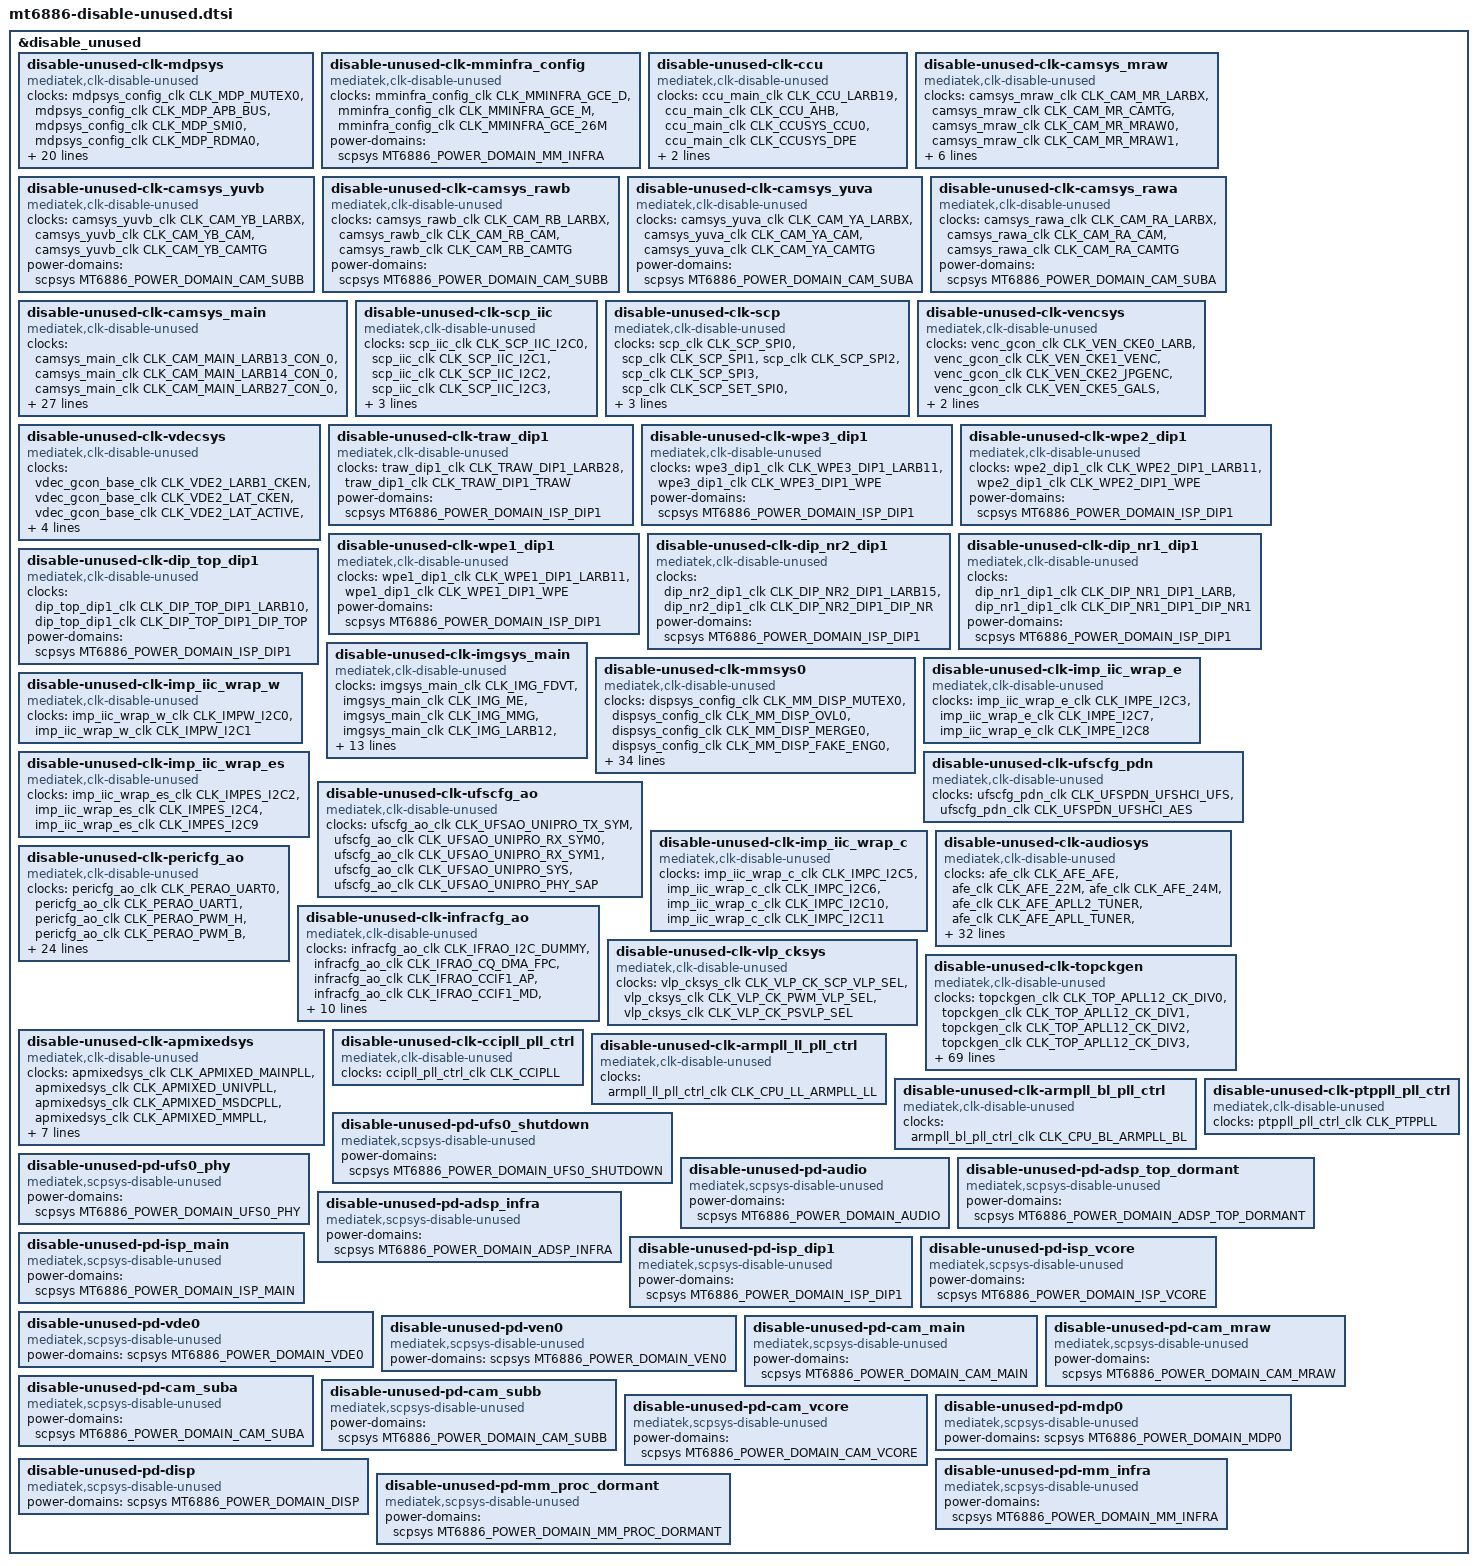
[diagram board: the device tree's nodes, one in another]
// SPDX-License-Identifier: GPL-2.0-only OR BSD-2-Clause
/*
 * Copyright (C) 2022 MediaTek Inc.
 * Author: Chong-ming Wei <chong-ming.wei@mediatek.com>
 */

&disable_unused {
	status = "okay";
	disable-unused-clk-mdpsys {
		compatible = "mediatek,clk-disable-unused";
		clocks =
			<&mdpsys_config_clk CLK_MDP_MUTEX0>,
			<&mdpsys_config_clk CLK_MDP_APB_BUS>,
			<&mdpsys_config_clk CLK_MDP_SMI0>,
			<&mdpsys_config_clk CLK_MDP_RDMA0>,
			<&mdpsys_config_clk CLK_MDP_HDR0>,
			<&mdpsys_config_clk CLK_MDP_AAL0>,
			<&mdpsys_config_clk CLK_MDP_RSZ0>,
			<&mdpsys_config_clk CLK_MDP_TDSHP0>,
			<&mdpsys_config_clk CLK_MDP_COLOR0>,
			<&mdpsys_config_clk CLK_MDP_WROT0>,
			<&mdpsys_config_clk CLK_MDP_FAKE_ENG0>,
			<&mdpsys_config_clk CLK_MDP_DL_RELAY0>,
			<&mdpsys_config_clk CLK_MDP_DL_RELAY1>,
			<&mdpsys_config_clk CLK_MDP_RDMA1>,
			<&mdpsys_config_clk CLK_MDP_HDR1>,
			<&mdpsys_config_clk CLK_MDP_AAL1>,
			<&mdpsys_config_clk CLK_MDP_RSZ1>,
			<&mdpsys_config_clk CLK_MDP_TDSHP1>,
			<&mdpsys_config_clk CLK_MDP_COLOR1>,
			<&mdpsys_config_clk CLK_MDP_WROT1>,
			<&mdpsys_config_clk CLK_MDP_DLO_ASYNC0>,
			<&mdpsys_config_clk CLK_MDP_DLO_ASYNC1>,
			<&mdpsys_config_clk CLK_MDP_HRE_TOP_MDPSYS>;
			power-domains = <&scpsys MT6886_POWER_DOMAIN_MDP0>;
	};

	disable-unused-clk-mminfra_config {
		compatible = "mediatek,clk-disable-unused";
		clocks =
			<&mminfra_config_clk CLK_MMINFRA_GCE_D>,
			<&mminfra_config_clk CLK_MMINFRA_GCE_M>,
			<&mminfra_config_clk CLK_MMINFRA_GCE_26M>;
			power-domains = <&scpsys MT6886_POWER_DOMAIN_MM_INFRA>;
	};

	disable-unused-clk-ccu {
		compatible = "mediatek,clk-disable-unused";
		clocks =
			<&ccu_main_clk CLK_CCU_LARB19>,
			<&ccu_main_clk CLK_CCU_AHB>,
			<&ccu_main_clk CLK_CCUSYS_CCU0>,
			<&ccu_main_clk CLK_CCUSYS_DPE>;
			power-domains = <&scpsys MT6886_POWER_DOMAIN_CAM_MAIN>;
	};

	disable-unused-clk-camsys_mraw {
		compatible = "mediatek,clk-disable-unused";
		clocks =
			<&camsys_mraw_clk CLK_CAM_MR_LARBX>,
			<&camsys_mraw_clk CLK_CAM_MR_CAMTG>,
			<&camsys_mraw_clk CLK_CAM_MR_MRAW0>,
			<&camsys_mraw_clk CLK_CAM_MR_MRAW1>,
			<&camsys_mraw_clk CLK_CAM_MR_MRAW2>,
			<&camsys_mraw_clk CLK_CAM_MR_MRAW3>,
			<&camsys_mraw_clk CLK_CAM_MR_PDA0>,
			<&camsys_mraw_clk CLK_CAM_MR_PDA1>;
			power-domains = <&scpsys MT6886_POWER_DOMAIN_CAM_MRAW>;
	};

	disable-unused-clk-camsys_yuvb {
		compatible = "mediatek,clk-disable-unused";
		clocks =
			<&camsys_yuvb_clk CLK_CAM_YB_LARBX>,
			<&camsys_yuvb_clk CLK_CAM_YB_CAM>,
			<&camsys_yuvb_clk CLK_CAM_YB_CAMTG>;
			power-domains = <&scpsys MT6886_POWER_DOMAIN_CAM_SUBB>;
	};

	disable-unused-clk-camsys_rawb {
		compatible = "mediatek,clk-disable-unused";
		clocks =
			<&camsys_rawb_clk CLK_CAM_RB_LARBX>,
			<&camsys_rawb_clk CLK_CAM_RB_CAM>,
			<&camsys_rawb_clk CLK_CAM_RB_CAMTG>;
			power-domains = <&scpsys MT6886_POWER_DOMAIN_CAM_SUBB>;
	};

	disable-unused-clk-camsys_yuva {
		compatible = "mediatek,clk-disable-unused";
		clocks =
			<&camsys_yuva_clk CLK_CAM_YA_LARBX>,
			<&camsys_yuva_clk CLK_CAM_YA_CAM>,
			<&camsys_yuva_clk CLK_CAM_YA_CAMTG>;
			power-domains = <&scpsys MT6886_POWER_DOMAIN_CAM_SUBA>;
	};

	disable-unused-clk-camsys_rawa {
		compatible = "mediatek,clk-disable-unused";
		clocks =
			<&camsys_rawa_clk CLK_CAM_RA_LARBX>,
			<&camsys_rawa_clk CLK_CAM_RA_CAM>,
			<&camsys_rawa_clk CLK_CAM_RA_CAMTG>;
			power-domains = <&scpsys MT6886_POWER_DOMAIN_CAM_SUBA>;
	};

	disable-unused-clk-camsys_main {
		compatible = "mediatek,clk-disable-unused";
		clocks =
			<&camsys_main_clk CLK_CAM_MAIN_LARB13_CON_0>,
			<&camsys_main_clk CLK_CAM_MAIN_LARB14_CON_0>,
			<&camsys_main_clk CLK_CAM_MAIN_LARB27_CON_0>,
			<&camsys_main_clk CLK_CAM_MAIN_LARB29_CON_0>,
			<&camsys_main_clk CLK_CAM_MAIN_CAM_CON_0>,
			<&camsys_main_clk CLK_CAM_MAIN_CAM_SUBA_CON_0>,
			<&camsys_main_clk CLK_CAM_MAIN_CAM_SUBB_CON_0>,
			<&camsys_main_clk CLK_CAM_MAIN_CAM_SUBC_CON_0>,
			<&camsys_main_clk CLK_CAM_MAIN_CAM_MRAW_CON_0>,
			<&camsys_main_clk CLK_CAM_MAIN_CAMTG_CON_0>,
			<&camsys_main_clk CLK_CAM_MAIN_SENINF_CON_0>,
			<&camsys_main_clk CLK_CAM_MAIN_CAMSV_TOP_CON_0>,
			<&camsys_main_clk CLK_CAM_MAIN_ADLRD_CON_0>,
			<&camsys_main_clk CLK_CAM_MAIN_ADLWR_CON_0>,
			<&camsys_main_clk CLK_CAM_MAIN_UISP_CON_0>,
			<&camsys_main_clk CLK_CAM_MAIN_FAKE_ENG_CON_0>,
			<&camsys_main_clk CLK_CAM_MAIN_CAM2MM0_GALS_CON_0>,
			<&camsys_main_clk CLK_CAM_MAIN_CAM2MM1_GALS_CON_0>,
			<&camsys_main_clk CLK_CAM_MAIN_CAM2SYS_GALS_CON_0>,
			<&camsys_main_clk CLK_CAM_MAIN_CAM2MM2_GALS_CON_0>,
			<&camsys_main_clk CLK_CAM_MAIN_CCUSYS_CON_0>,
			<&camsys_main_clk CLK_CAM_MAIN_IPS_CON_0>,
			<&camsys_main_clk CLK_CAM_MAIN_CAMSV_A_CON_1>,
			<&camsys_main_clk CLK_CAM_MAIN_CAMSV_B_CON_1>,
			<&camsys_main_clk CLK_CAM_MAIN_CAMSV_C_CON_1>,
			<&camsys_main_clk CLK_CAM_MAIN_CAMSV_D_CON_1>,
			<&camsys_main_clk CLK_CAM_MAIN_CAMSV_E_CON_1>,
			<&camsys_main_clk CLK_CAM_MAIN_CAMSV_CON_1>;
			power-domains = <&scpsys MT6886_POWER_DOMAIN_CAM_MAIN>;
	};

	disable-unused-clk-scp_iic {
		compatible = "mediatek,clk-disable-unused";
		clocks =
			<&scp_iic_clk CLK_SCP_IIC_I2C0>,
			<&scp_iic_clk CLK_SCP_IIC_I2C1>,
			<&scp_iic_clk CLK_SCP_IIC_I2C2>,
			<&scp_iic_clk CLK_SCP_IIC_I2C3>,
			<&scp_iic_clk CLK_SCP_IIC_I2C4>,
			<&scp_iic_clk CLK_SCP_IIC_I2C5>,
			<&scp_iic_clk CLK_SCP_IIC_I2C6>;
	};

	disable-unused-clk-scp {
		compatible = "mediatek,clk-disable-unused";
		clocks =
			<&scp_clk CLK_SCP_SPI0>,
			<&scp_clk CLK_SCP_SPI1>,
			<&scp_clk CLK_SCP_SPI2>,
			<&scp_clk CLK_SCP_SPI3>,
			<&scp_clk CLK_SCP_SET_SPI0>,
			<&scp_clk CLK_SCP_SET_SPI1>,
			<&scp_clk CLK_SCP_SET_SPI2>,
			<&scp_clk CLK_SCP_SET_SPI3>;
	};

	disable-unused-clk-vencsys {
		compatible = "mediatek,clk-disable-unused";
		clocks =
			<&venc_gcon_clk CLK_VEN_CKE0_LARB>,
			<&venc_gcon_clk CLK_VEN_CKE1_VENC>,
			<&venc_gcon_clk CLK_VEN_CKE2_JPGENC>,
			<&venc_gcon_clk CLK_VEN_CKE5_GALS>,
			<&venc_gcon_clk CLK_VEN_CKE6_GALS_SRAM>;
			power-domains = <&scpsys MT6886_POWER_DOMAIN_VEN0>;
	};

	disable-unused-clk-vdecsys {
		compatible = "mediatek,clk-disable-unused";
		clocks =
			<&vdec_gcon_base_clk CLK_VDE2_LARB1_CKEN>,
			<&vdec_gcon_base_clk CLK_VDE2_LAT_CKEN>,
			<&vdec_gcon_base_clk CLK_VDE2_LAT_ACTIVE>,
			<&vdec_gcon_base_clk CLK_VDE2_MINI_MDP_EN>,
			<&vdec_gcon_base_clk CLK_VDE2_VDEC_CKEN>,
			<&vdec_gcon_base_clk CLK_VDE2_VDEC_ACTIVE>;
			power-domains = <&scpsys MT6886_POWER_DOMAIN_VDE0>;
	};

	disable-unused-clk-traw_dip1 {
		compatible = "mediatek,clk-disable-unused";
		clocks =
			<&traw_dip1_clk CLK_TRAW_DIP1_LARB28>,
			<&traw_dip1_clk CLK_TRAW_DIP1_TRAW>;
			power-domains = <&scpsys MT6886_POWER_DOMAIN_ISP_DIP1>;
	};

	disable-unused-clk-wpe3_dip1 {
		compatible = "mediatek,clk-disable-unused";
		clocks =
			<&wpe3_dip1_clk CLK_WPE3_DIP1_LARB11>,
			<&wpe3_dip1_clk CLK_WPE3_DIP1_WPE>;
			power-domains = <&scpsys MT6886_POWER_DOMAIN_ISP_DIP1>;
	};

	disable-unused-clk-wpe2_dip1 {
		compatible = "mediatek,clk-disable-unused";
		clocks =
			<&wpe2_dip1_clk CLK_WPE2_DIP1_LARB11>,
			<&wpe2_dip1_clk CLK_WPE2_DIP1_WPE>;
			power-domains = <&scpsys MT6886_POWER_DOMAIN_ISP_DIP1>;
	};

	disable-unused-clk-wpe1_dip1 {
		compatible = "mediatek,clk-disable-unused";
		clocks =
			<&wpe1_dip1_clk CLK_WPE1_DIP1_LARB11>,
			<&wpe1_dip1_clk CLK_WPE1_DIP1_WPE>;
			power-domains = <&scpsys MT6886_POWER_DOMAIN_ISP_DIP1>;
	};

	disable-unused-clk-dip_nr2_dip1 {
		compatible = "mediatek,clk-disable-unused";
		clocks =
			<&dip_nr2_dip1_clk CLK_DIP_NR2_DIP1_LARB15>,
			<&dip_nr2_dip1_clk CLK_DIP_NR2_DIP1_DIP_NR>;
			power-domains = <&scpsys MT6886_POWER_DOMAIN_ISP_DIP1>;
	};

	disable-unused-clk-dip_nr1_dip1 {
		compatible = "mediatek,clk-disable-unused";
		clocks =
			<&dip_nr1_dip1_clk CLK_DIP_NR1_DIP1_LARB>,
			<&dip_nr1_dip1_clk CLK_DIP_NR1_DIP1_DIP_NR1>;
			power-domains = <&scpsys MT6886_POWER_DOMAIN_ISP_DIP1>;
	};

	disable-unused-clk-dip_top_dip1 {
		compatible = "mediatek,clk-disable-unused";
		clocks =
			<&dip_top_dip1_clk CLK_DIP_TOP_DIP1_LARB10>,
			<&dip_top_dip1_clk CLK_DIP_TOP_DIP1_DIP_TOP>;
			power-domains = <&scpsys MT6886_POWER_DOMAIN_ISP_DIP1>;
	};

	disable-unused-clk-imgsys_main {
		compatible = "mediatek,clk-disable-unused";
		clocks =
			<&imgsys_main_clk CLK_IMG_FDVT>,
			<&imgsys_main_clk CLK_IMG_ME>,
			<&imgsys_main_clk CLK_IMG_MMG>,
			<&imgsys_main_clk CLK_IMG_LARB12>,
			<&imgsys_main_clk CLK_IMG_LARB9>,
			<&imgsys_main_clk CLK_IMG_TRAW0>,
			<&imgsys_main_clk CLK_IMG_TRAW1>,
			<&imgsys_main_clk CLK_IMG_VCORE_GALS>,
			<&imgsys_main_clk CLK_IMG_DIP0>,
			<&imgsys_main_clk CLK_IMG_WPE0>,
			<&imgsys_main_clk CLK_IMG_IPE>,
			<&imgsys_main_clk CLK_IMG_WPE1>,
			<&imgsys_main_clk CLK_IMG_WPE2>,
			<&imgsys_main_clk CLK_IMG_AVS>,
			<&imgsys_main_clk CLK_IMG_GALS>;
			power-domains = <&scpsys MT6886_POWER_DOMAIN_ISP_MAIN>;
	};

	disable-unused-clk-mmsys0 {
		compatible = "mediatek,clk-disable-unused";
		clocks =
			<&dispsys_config_clk CLK_MM_DISP_MUTEX0>,
			<&dispsys_config_clk CLK_MM_DISP_OVL0>,
			<&dispsys_config_clk CLK_MM_DISP_MERGE0>,
			<&dispsys_config_clk CLK_MM_DISP_FAKE_ENG0>,
			<&dispsys_config_clk CLK_MM_INLINEROT0>,
			<&dispsys_config_clk CLK_MM_DISP_WDMA0>,
			<&dispsys_config_clk CLK_MM_DISP_FAKE_ENG1>,
			<&dispsys_config_clk CLK_MM_DISP_OVL0_2L_NW>,
			<&dispsys_config_clk CLK_MM_DISP_RDMA0>,
			<&dispsys_config_clk CLK_MM_DISP_RDMA1>,
			<&dispsys_config_clk CLK_MM_DISP_RSZ0>,
			<&dispsys_config_clk CLK_MM_DISP_COLOR0>,
			<&dispsys_config_clk CLK_MM_DISP_CCORR0>,
			<&dispsys_config_clk CLK_MM_DISP_CCORR1>,
			<&dispsys_config_clk CLK_MM_DISP_AAL0>,
			<&dispsys_config_clk CLK_MM_DISP_GAMMA0>,
			<&dispsys_config_clk CLK_MM_DISP_POSTMASK0>,
			<&dispsys_config_clk CLK_MM_DISP_DITHER0>,
			<&dispsys_config_clk CLK_MM_DISP_CM0>,
			<&dispsys_config_clk CLK_MM_DISP_SPR0>,
			<&dispsys_config_clk CLK_MM_DISP_DSC_WRAP0>,
			<&dispsys_config_clk CLK_MM_FMM_DISP_DSI0>,
			<&dispsys_config_clk CLK_MM_DISP_UFBC_WDMA0>,
			<&dispsys_config_clk CLK_MM_DISP_WDMA1>,
			<&dispsys_config_clk CLK_MM_APB_BUS>,
			<&dispsys_config_clk CLK_MM_DISP_C3D0>,
			<&dispsys_config_clk CLK_MM_DISP_Y2R0>,
			<&dispsys_config_clk CLK_MM_DISP_CHIST0>,
			<&dispsys_config_clk CLK_MM_DISP_CHIST1>,
			<&dispsys_config_clk CLK_MM_DISP_OVL0_2L>,
			<&dispsys_config_clk CLK_MM_DISP_DLI_ASYNC3>,
			<&dispsys_config_clk CLK_MM_DISP_DLO_ASYNC3>,
			<&dispsys_config_clk CLK_MM_DISP_OVL1_2L>,
			<&dispsys_config_clk CLK_MM_DISP_OVL1_2L_NW>,
			<&dispsys_config_clk CLK_MM_SMI_COMMON>,
			<&dispsys_config_clk CLK_MM_DISP_DSI0>,
			<&dispsys_config_clk CLK_MM_SIG_EMI>;
			power-domains = <&scpsys MT6886_POWER_DOMAIN_DISP>;
	};

	disable-unused-clk-imp_iic_wrap_e {
		compatible = "mediatek,clk-disable-unused";
		clocks =
			<&imp_iic_wrap_e_clk CLK_IMPE_I2C3>,
			<&imp_iic_wrap_e_clk CLK_IMPE_I2C7>,
			<&imp_iic_wrap_e_clk CLK_IMPE_I2C8>;
	};

	disable-unused-clk-imp_iic_wrap_w {
		compatible = "mediatek,clk-disable-unused";
		clocks =
			<&imp_iic_wrap_w_clk CLK_IMPW_I2C0>,
			<&imp_iic_wrap_w_clk CLK_IMPW_I2C1>;
	};

	disable-unused-clk-imp_iic_wrap_es {
		compatible = "mediatek,clk-disable-unused";
		clocks =
			<&imp_iic_wrap_es_clk CLK_IMPES_I2C2>,
			<&imp_iic_wrap_es_clk CLK_IMPES_I2C4>,
			<&imp_iic_wrap_es_clk CLK_IMPES_I2C9>;
	};

	disable-unused-clk-ufscfg_pdn {
		compatible = "mediatek,clk-disable-unused";
		clocks =
			<&ufscfg_pdn_clk CLK_UFSPDN_UFSHCI_UFS>,
			<&ufscfg_pdn_clk CLK_UFSPDN_UFSHCI_AES>;
	};

	disable-unused-clk-ufscfg_ao {
		compatible = "mediatek,clk-disable-unused";
		clocks =
			<&ufscfg_ao_clk CLK_UFSAO_UNIPRO_TX_SYM>,
			<&ufscfg_ao_clk CLK_UFSAO_UNIPRO_RX_SYM0>,
			<&ufscfg_ao_clk CLK_UFSAO_UNIPRO_RX_SYM1>,
			<&ufscfg_ao_clk CLK_UFSAO_UNIPRO_SYS>,
			<&ufscfg_ao_clk CLK_UFSAO_UNIPRO_PHY_SAP>;
	};

	disable-unused-clk-imp_iic_wrap_c {
		compatible = "mediatek,clk-disable-unused";
		clocks =
			<&imp_iic_wrap_c_clk CLK_IMPC_I2C5>,
			<&imp_iic_wrap_c_clk CLK_IMPC_I2C6>,
			<&imp_iic_wrap_c_clk CLK_IMPC_I2C10>,
			<&imp_iic_wrap_c_clk CLK_IMPC_I2C11>;
	};

	disable-unused-clk-audiosys {
		compatible = "mediatek,clk-disable-unused";
		clocks =
			<&afe_clk CLK_AFE_AFE>,
			<&afe_clk CLK_AFE_22M>,
			<&afe_clk CLK_AFE_24M>,
			<&afe_clk CLK_AFE_APLL2_TUNER>,
			<&afe_clk CLK_AFE_APLL_TUNER>,
			<&afe_clk CLK_AFE_TDM>,
			<&afe_clk CLK_AFE_ADC>,
			<&afe_clk CLK_AFE_DAC>,
			<&afe_clk CLK_AFE_DAC_PREDIS>,
			<&afe_clk CLK_AFE_TML>,
			<&afe_clk CLK_AFE_NLE>,
			<&afe_clk CLK_AFE_GENERAL3_ASRC>,
			<&afe_clk CLK_AFE_CONNSYS_I2S_ASRC>,
			<&afe_clk CLK_AFE_GENERAL1_ASRC>,
			<&afe_clk CLK_AFE_GENERAL2_ASRC>,
			<&afe_clk CLK_AFE_DAC_HIRES>,
			<&afe_clk CLK_AFE_ADC_HIRES>,
			<&afe_clk CLK_AFE_ADC_HIRES_TML>,
			<&afe_clk CLK_AFE_ADDA6_ADC>,
			<&afe_clk CLK_AFE_ADDA6_ADC_HIRES>,
			<&afe_clk CLK_AFE_3RD_DAC>,
			<&afe_clk CLK_AFE_3RD_DAC_PREDIS>,
			<&afe_clk CLK_AFE_3RD_DAC_TML>,
			<&afe_clk CLK_AFE_3RD_DAC_HIRES>,
			<&afe_clk CLK_AFE_I2S5_BCLK>,
			<&afe_clk CLK_AFE_I2S6_BCLK>,
			<&afe_clk CLK_AFE_I2S7_BCLK>,
			<&afe_clk CLK_AFE_I2S8_BCLK>,
			<&afe_clk CLK_AFE_I2S9_BCLK>,
			<&afe_clk CLK_AFE_ETDM_IN0_BCLK>,
			<&afe_clk CLK_AFE_ETDM_OUT0_BCLK>,
			<&afe_clk CLK_AFE_I2S1_BCLK>,
			<&afe_clk CLK_AFE_I2S2_BCLK>,
			<&afe_clk CLK_AFE_I2S3_BCLK>,
			<&afe_clk CLK_AFE_I2S4_BCLK>,
			<&afe_clk CLK_AFE_ETDM_IN1_BCLK>,
			<&afe_clk CLK_AFE_ETDM_OUT1_BCLK>;
			power-domains = <&scpsys MT6886_POWER_DOMAIN_AUDIO>;
	};

	disable-unused-clk-pericfg_ao {
		compatible = "mediatek,clk-disable-unused";
		clocks =
			<&pericfg_ao_clk CLK_PERAO_UART0>,
			<&pericfg_ao_clk CLK_PERAO_UART1>,
			<&pericfg_ao_clk CLK_PERAO_PWM_H>,
			<&pericfg_ao_clk CLK_PERAO_PWM_B>,
			<&pericfg_ao_clk CLK_PERAO_PWM_FB1>,
			<&pericfg_ao_clk CLK_PERAO_PWM_FB2>,
			<&pericfg_ao_clk CLK_PERAO_PWM_FB3>,
			<&pericfg_ao_clk CLK_PERAO_PWM_FB4>,
			<&pericfg_ao_clk CLK_PERAO_BTIF_B>,
			<&pericfg_ao_clk CLK_PERAO_DISP_PWM0>,
			<&pericfg_ao_clk CLK_PERAO_SPI0_B>,
			<&pericfg_ao_clk CLK_PERAO_SPI1_B>,
			<&pericfg_ao_clk CLK_PERAO_SPI2_B>,
			<&pericfg_ao_clk CLK_PERAO_SPI3_B>,
			<&pericfg_ao_clk CLK_PERAO_SPI4_B>,
			<&pericfg_ao_clk CLK_PERAO_SPI5_B>,
			<&pericfg_ao_clk CLK_PERAO_SPI6_B>,
			<&pericfg_ao_clk CLK_PERAO_SPI7_B>,
			<&pericfg_ao_clk CLK_PERAO_APDMA>,
			<&pericfg_ao_clk CLK_PERAO_USB_SYS>,
			<&pericfg_ao_clk CLK_PERAO_USB_XHCI>,
			<&pericfg_ao_clk CLK_PERAO_USB_BUS>,
			<&pericfg_ao_clk CLK_PERAO_MSDC1>,
			<&pericfg_ao_clk CLK_PERAO_MSDC1_H>,
			<&pericfg_ao_clk CLK_PERAO_AUDIO_SLV_CKP>,
			<&pericfg_ao_clk CLK_PERAO_AUDIO_MST_CKP>,
			<&pericfg_ao_clk CLK_PERAO_INTBUS_CKP>,
			<&pericfg_ao_clk CLK_PERAO_AUDIO_MST_IDLE_EN>;
	};

	disable-unused-clk-infracfg_ao {
		compatible = "mediatek,clk-disable-unused";
		clocks =
			<&infracfg_ao_clk CLK_IFRAO_I2C_DUMMY>,
			<&infracfg_ao_clk CLK_IFRAO_CQ_DMA_FPC>,
			<&infracfg_ao_clk CLK_IFRAO_CCIF1_AP>,
			<&infracfg_ao_clk CLK_IFRAO_CCIF1_MD>,
			<&infracfg_ao_clk CLK_IFRAO_CCIF_AP>,
			<&infracfg_ao_clk CLK_IFRAO_CCIF_MD>,
			<&infracfg_ao_clk CLK_IFRAO_CLDMA_BCLK>,
			<&infracfg_ao_clk CLK_IFRAO_CQ_DMA>,
			<&infracfg_ao_clk CLK_IFRAO_CCIF5_MD>,
			<&infracfg_ao_clk CLK_IFRAO_CCIF2_AP>,
			<&infracfg_ao_clk CLK_IFRAO_CCIF2_MD>,
			<&infracfg_ao_clk CLK_IFRAO_DPMAIF_MAIN>,
			<&infracfg_ao_clk CLK_IFRAO_CCIF4_MD>,
			<&infracfg_ao_clk CLK_IFRAO_RG_MMW_DPMAIF26M>;
	};

	disable-unused-clk-vlp_cksys {
		compatible = "mediatek,clk-disable-unused";
		clocks =
			<&vlp_cksys_clk CLK_VLP_CK_SCP_VLP_SEL>,
			<&vlp_cksys_clk CLK_VLP_CK_PWM_VLP_SEL>,
			<&vlp_cksys_clk CLK_VLP_CK_PSVLP_SEL>;
	};

	disable-unused-clk-topckgen {
		compatible = "mediatek,clk-disable-unused";
		clocks =
			<&topckgen_clk CLK_TOP_APLL12_CK_DIV0>,
			<&topckgen_clk CLK_TOP_APLL12_CK_DIV1>,
			<&topckgen_clk CLK_TOP_APLL12_CK_DIV2>,
			<&topckgen_clk CLK_TOP_APLL12_CK_DIV3>,
			<&topckgen_clk CLK_TOP_APLL12_CK_DIV4>,
			<&topckgen_clk CLK_TOP_APLL12_CK_DIVB>,
			<&topckgen_clk CLK_TOP_APLL12_CK_DIV5>,
			<&topckgen_clk CLK_TOP_APLL12_CK_DIV6>,
			<&topckgen_clk CLK_TOP_APLL12_CK_DIV7>,
			<&topckgen_clk CLK_TOP_APLL12_CK_DIV8>,
			<&topckgen_clk CLK_TOP_APLL12_CK_DIV9>,
			<&topckgen_clk CLK_TOP_APLL12_CK_DIV_ETDM_IN1>,
			<&topckgen_clk CLK_TOP_APLL12_CK_DIV_ETDM_OUT1>,
			<&topckgen_clk CLK_TOP_DISP0_SEL>,
			<&topckgen_clk CLK_TOP_MDP0_SEL>,
			<&topckgen_clk CLK_TOP_MMINFRA_SEL>,
			<&topckgen_clk CLK_TOP_MMUP_SEL>,
			<&topckgen_clk CLK_TOP_DSP_SEL>,
			<&topckgen_clk CLK_TOP_CAMTG_SEL>,
			<&topckgen_clk CLK_TOP_CAMTG2_SEL>,
			<&topckgen_clk CLK_TOP_CAMTG3_SEL>,
			<&topckgen_clk CLK_TOP_CAMTG4_SEL>,
			<&topckgen_clk CLK_TOP_CAMTG5_SEL>,
			<&topckgen_clk CLK_TOP_CAMTG6_SEL>,
			<&topckgen_clk CLK_TOP_UART_SEL>,
			<&topckgen_clk CLK_TOP_SPI_SEL>,
			<&topckgen_clk CLK_TOP_MSDC_MACRO_SEL>,
			<&topckgen_clk CLK_TOP_MSDC30_1_SEL>,
			<&topckgen_clk CLK_TOP_MSDC30_2_SEL>,
			<&topckgen_clk CLK_TOP_AUDIO_SEL>,
			<&topckgen_clk CLK_TOP_AUD_INTBUS_SEL>,
			<&topckgen_clk CLK_TOP_DISP_PWM_SEL>,
			<&topckgen_clk CLK_TOP_USB_TOP_SEL>,
			<&topckgen_clk CLK_TOP_USB_XHCI_SEL>,
			<&topckgen_clk CLK_TOP_I2C_SEL>,
			<&topckgen_clk CLK_TOP_SENINF_SEL>,
			<&topckgen_clk CLK_TOP_SENINF1_SEL>,
			<&topckgen_clk CLK_TOP_SENINF2_SEL>,
			<&topckgen_clk CLK_TOP_SENINF3_SEL>,
			<&topckgen_clk CLK_TOP_AUD_ENGEN1_SEL>,
			<&topckgen_clk CLK_TOP_AUD_ENGEN2_SEL>,
			<&topckgen_clk CLK_TOP_AES_UFSFDE_SEL>,
			<&topckgen_clk CLK_TOP_U_SEL>,
			<&topckgen_clk CLK_TOP_U_MBIST_SEL>,
			<&topckgen_clk CLK_TOP_AUD_1_SEL>,
			<&topckgen_clk CLK_TOP_AUD_2_SEL>,
			<&topckgen_clk CLK_TOP_ADSP_SEL>,
			<&topckgen_clk CLK_TOP_VENC_SEL>,
			<&topckgen_clk CLK_TOP_VDEC_SEL>,
			<&topckgen_clk CLK_TOP_PWM_SEL>,
			<&topckgen_clk CLK_TOP_AUDIO_H_SEL>,
			<&topckgen_clk CLK_TOP_DSI_OCC_SEL>,
			<&topckgen_clk CLK_TOP_CCU_AHB_SEL>,
			<&topckgen_clk CLK_TOP_IMG1_SEL>,
			<&topckgen_clk CLK_TOP_IPE_SEL>,
			<&topckgen_clk CLK_TOP_CAM_SEL>,
			<&topckgen_clk CLK_TOP_CCUSYS_SEL>,
			<&topckgen_clk CLK_TOP_CAMTM_SEL>,
			<&topckgen_clk CLK_TOP_CSI_OCC_SCAN_SEL>,
			<&topckgen_clk CLK_TOP_IPSWEST_SEL>,
			<&topckgen_clk CLK_TOP_IPSNORTH_SEL>,
			<&topckgen_clk CLK_TOP_APLL_I2S0_MCK_SEL>,
			<&topckgen_clk CLK_TOP_APLL_I2S1_MCK_SEL>,
			<&topckgen_clk CLK_TOP_APLL_I2S2_MCK_SEL>,
			<&topckgen_clk CLK_TOP_APLL_I2S3_MCK_SEL>,
			<&topckgen_clk CLK_TOP_APLL_I2S4_MCK_SEL>,
			<&topckgen_clk CLK_TOP_APLL_I2S5_MCK_SEL>,
			<&topckgen_clk CLK_TOP_APLL_I2S6_MCK_SEL>,
			<&topckgen_clk CLK_TOP_APLL_I2S7_MCK_SEL>,
			<&topckgen_clk CLK_TOP_APLL_I2S8_MCK_SEL>,
			<&topckgen_clk CLK_TOP_APLL_I2S9_MCK_SEL>,
			<&topckgen_clk CLK_TOP_APLL_ETDM_IN1_MCK_SEL>,
			<&topckgen_clk CLK_TOP_APLL_ETDM_OUT1_MCK_SEL>;
	};

	disable-unused-clk-apmixedsys {
		compatible = "mediatek,clk-disable-unused";
		clocks =
			<&apmixedsys_clk CLK_APMIXED_MAINPLL>,
			<&apmixedsys_clk CLK_APMIXED_UNIVPLL>,
			<&apmixedsys_clk CLK_APMIXED_MSDCPLL>,
			<&apmixedsys_clk CLK_APMIXED_MMPLL>,
			<&apmixedsys_clk CLK_APMIXED_ADSPPLL>,
			<&apmixedsys_clk CLK_APMIXED_UFSPLL>,
			<&apmixedsys_clk CLK_APMIXED_APLL1>,
			<&apmixedsys_clk CLK_APMIXED_APLL2>,
			<&apmixedsys_clk CLK_APMIXED_MPLL>,
			<&apmixedsys_clk CLK_APMIXED_EMIPLL>,
			<&apmixedsys_clk CLK_APMIXED_IMGPLL>;
	};

	disable-unused-clk-ccipll_pll_ctrl {
		compatible = "mediatek,clk-disable-unused";
		clocks =
			<&ccipll_pll_ctrl_clk CLK_CCIPLL>;
	};

	disable-unused-clk-armpll_ll_pll_ctrl {
		compatible = "mediatek,clk-disable-unused";
		clocks =
			<&armpll_ll_pll_ctrl_clk CLK_CPU_LL_ARMPLL_LL>;
	};

	disable-unused-clk-armpll_bl_pll_ctrl {
		compatible = "mediatek,clk-disable-unused";
		clocks =
			<&armpll_bl_pll_ctrl_clk CLK_CPU_BL_ARMPLL_BL>;
	};

	disable-unused-clk-ptppll_pll_ctrl {
		compatible = "mediatek,clk-disable-unused";
		clocks =
			<&ptppll_pll_ctrl_clk CLK_PTPPLL>;
	};

	disable-unused-pd-ufs0_shutdown {
		compatible = "mediatek,scpsys-disable-unused";
		power-domains = <&scpsys MT6886_POWER_DOMAIN_UFS0_SHUTDOWN>;
	};

	disable-unused-pd-ufs0_phy {
		compatible = "mediatek,scpsys-disable-unused";
		power-domains = <&scpsys MT6886_POWER_DOMAIN_UFS0_PHY>;
	};

	disable-unused-pd-audio {
		compatible = "mediatek,scpsys-disable-unused";
		power-domains = <&scpsys MT6886_POWER_DOMAIN_AUDIO>;
	};

	disable-unused-pd-adsp_top_dormant {
		compatible = "mediatek,scpsys-disable-unused";
		power-domains = <&scpsys MT6886_POWER_DOMAIN_ADSP_TOP_DORMANT>;
	};

	disable-unused-pd-adsp_infra {
		compatible = "mediatek,scpsys-disable-unused";
		power-domains = <&scpsys MT6886_POWER_DOMAIN_ADSP_INFRA>;
	};

	disable-unused-pd-isp_main {
		compatible = "mediatek,scpsys-disable-unused";
		power-domains = <&scpsys MT6886_POWER_DOMAIN_ISP_MAIN>;
	};

	disable-unused-pd-isp_dip1 {
		compatible = "mediatek,scpsys-disable-unused";
		power-domains = <&scpsys MT6886_POWER_DOMAIN_ISP_DIP1>;
	};

	disable-unused-pd-isp_vcore {
		compatible = "mediatek,scpsys-disable-unused";
		power-domains = <&scpsys MT6886_POWER_DOMAIN_ISP_VCORE>;
	};

	disable-unused-pd-vde0 {
		compatible = "mediatek,scpsys-disable-unused";
		power-domains = <&scpsys MT6886_POWER_DOMAIN_VDE0>;
	};

	disable-unused-pd-ven0 {
		compatible = "mediatek,scpsys-disable-unused";
		power-domains = <&scpsys MT6886_POWER_DOMAIN_VEN0>;
	};

	disable-unused-pd-cam_main {
		compatible = "mediatek,scpsys-disable-unused";
		power-domains = <&scpsys MT6886_POWER_DOMAIN_CAM_MAIN>;
	};

	disable-unused-pd-cam_mraw {
		compatible = "mediatek,scpsys-disable-unused";
		power-domains = <&scpsys MT6886_POWER_DOMAIN_CAM_MRAW>;
	};

	disable-unused-pd-cam_suba {
		compatible = "mediatek,scpsys-disable-unused";
		power-domains = <&scpsys MT6886_POWER_DOMAIN_CAM_SUBA>;
	};

	disable-unused-pd-cam_subb {
		compatible = "mediatek,scpsys-disable-unused";
		power-domains = <&scpsys MT6886_POWER_DOMAIN_CAM_SUBB>;
	};

	disable-unused-pd-cam_vcore {
		compatible = "mediatek,scpsys-disable-unused";
		power-domains = <&scpsys MT6886_POWER_DOMAIN_CAM_VCORE>;
	};

	disable-unused-pd-mdp0 {
		compatible = "mediatek,scpsys-disable-unused";
		power-domains = <&scpsys MT6886_POWER_DOMAIN_MDP0>;
	};

	disable-unused-pd-disp {
		compatible = "mediatek,scpsys-disable-unused";
		power-domains = <&scpsys MT6886_POWER_DOMAIN_DISP>;
	};

	disable-unused-pd-mm_infra {
		compatible = "mediatek,scpsys-disable-unused";
		power-domains = <&scpsys MT6886_POWER_DOMAIN_MM_INFRA>;
	};

	disable-unused-pd-mm_proc_dormant {
		compatible = "mediatek,scpsys-disable-unused";
		power-domains = <&scpsys MT6886_POWER_DOMAIN_MM_PROC_DORMANT>;
	};
};
